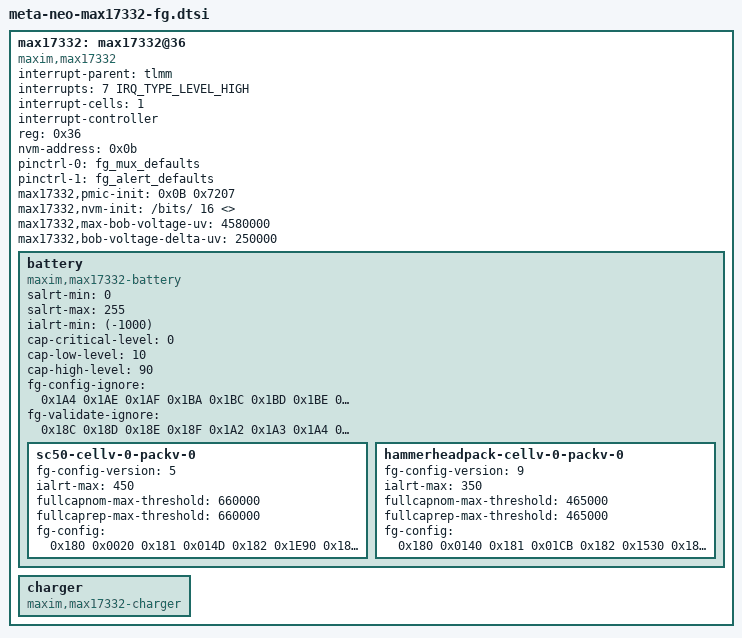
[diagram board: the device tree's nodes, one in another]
/*
MAX17332 is a multifunction device with battery, charger.
Required properties:
 - compatible : Must be "maxim,max17332".
 - interrupt-parent : The parent interrupt controller.
 - interrupts : Interrupt number.
 - interrupt-controller : Mark the device node as an interrupt controller.
 - interrupt-cells : Should be one.
	- The cell is the max17332 local IRQ number
 - max17332,pmic-init : Register values for initialization.
 - max17332,nvm-init : Register values for non-volatile memory initialization.
Nodes:
- battery, charger
*/

max17332: max17332@36 {
    compatible = "maxim,max17332";
    interrupt-parent = <&tlmm>;
    interrupts = <7 IRQ_TYPE_LEVEL_HIGH>;
    interrupt-cells = <1>;
    interrupt-controller;
    reg = <0x36>;
    status= "ok";
    nvm-address = /bits/ 8 <0x0b>;
    pinctrl-names = "default", "alert_enable";
    pinctrl-0 = <&fg_mux_defaults>;
    pinctrl-1 = <&fg_alert_defaults>;
    max17332,pmic-init = /bits/ 16 <0x0B 0x7207>;
    max17332,nvm-init = /bits/ 16 <>;
    max17332,max-bob-voltage-uv = <4580000>;
    max17332,bob-voltage-delta-uv = <250000>;

    battery {
        compatible = "maxim,max17332-battery";
        status = "ok";
        /* Battery */
        salrt-min			= <0>;			/* Percent */
        salrt-max			= <255>;		/* Percent. Setting to 255 (0xFF) which is a special value that disables the salrt-max */
        ialrt-min			= <(-1000)>;	/* mA */

        cap-critical-level		= /bits/ 8 <0>;
        cap-low-level		= /bits/ 8 <10>;
        cap-high-level		= /bits/ 8 <90>;
        /* fuel gauge configuration - ini version 9 */
        /* these set of fuel gauge registers will not
         * be written when updating the fg-config
         */
        fg-config-ignore    = /bits/ 16 <
            0x1A4 0x1AE 0x1AF 0x1BA
            0x1BC 0x1BD 0x1BE 0x1BF
            0x1E0 0x1E1 0x1E6 0x1E7
            0x1E8 0x1E9 0x1EA 0x1EB
            0x1EC 0x1ED 0x1EE 0x1EF>;
        fg-validate-ignore  = /bits/ 16 <
            0x18C 0x18D 0x18E 0x18F
            0x1A2 0x1A3 0x1A4 0x1A5 0x1A6 0x1A7 0x1A8 0x1A9 0x1AA 0x1AB 0x1AC 0x1AD 0x1AE 0x1AF
            0x1BA 0x1BB 0x1BC 0x1BD 0x1BE 0x1BF
            0x1C5 0x1CC
            0x1E0 0x1E1 0x1E2 0x1E3 0x1E4 0x1E5 0x1E6 0x1E7 0x1E8 0x1E9 0x1EA 0x1EB 0x1EC 0x1ED 0x1EE 0x1EF>;

        /* Pack specific settings */
        sc50-cellv-0-packv-0 {
            fg-config-version   = /bits/ 8 <5>;
            ialrt-max           = <450>;    /* mA */
            fullcapnom-max-threshold    = <660000>;
            fullcaprep-max-threshold    = <660000>;
            fg-config                   = /bits/ 16 <
                0x180  0x0020
                0x181  0x014D
                0x182  0x1E90
                0x183  0x0F00
                0x184  0x0E2D
                0x185  0x1003
                0x186  0x0A80
                0x187  0x0796
                0x188  0x0527
                0x189  0x06E0
                0x18A  0x08F3
                0x18B  0x03CC
                0x18C  0xE095
                0x18D  0x3CEC
                0x18E  0x16CE
                0x18F  0xFF01
                0x190  0x897B
                0x191  0xA248
                0x192  0xB7E8
                0x193  0xBA7C
                0x194  0xBD50
                0x195  0xBF08
                0x196  0xC23C
                0x197  0xC50A
                0x198  0xC96D
                0x199  0xD19D
                0x19A  0xD86F
                0x19B  0xDD34
                0x19C  0x0514
                0x19D  0x0000
                0x19E  0xA55A
                0x19F  0x2686
                0x1A0  0x3050
                0x1A1  0x0640
                0x1A2  0x0000
                0x1A3  0x0000
                0x1A4  0x0000
                0x1A5  0x0370
                0x1A6  0x0390
                0x1A7  0x0A03
                0x1A8  0x0000
                0x1A9  0x0370
                0x1AA  0x0000
                0x1AB  0x0000
                0x1AC  0x0000
                0x1AD  0x0000
                0x1AE  0x0000
                0x1AF  0x0000
                0x1B0  0xF217
                0x1B1  0x0204
                0x1B2  0x3870
                0x1B3  0x0B0B
                0x1B4  0x0010
                0x1B5  0x027D
                0x1B6  0x023C
                0x1B7  0x4241
                0x1B8  0x0000
                0x1B9  0x02A6
                0x1BA  0x0000
                0x1BB  0x0909
                0x1BC  0x0000
                0x1BD  0x0000
                0x1BE  0x0000
                0x1BF  0x0000
                0x1C0  0xC23E
                0x1C1  0x008C
                0x1C2  0x1E10
                0x1C3  0x4F72
                0x1C4  0x0075
                0x1C5  0x0AD0
                0x1C6  0x0000
                0x1C7  0x2000
                0x1C8  0x4003
                0x1C9  0x5188
                0x1CA  0x71B0
                0x1CB  0x0800
                0x1CC  0x04E0
                0x1CD  0x0000
                0x1CE  0x03EB
                0x1CF  0x000B
                0x1D0  0x660A
                0x1D1  0x3118
                0x1D2  0xF000
                0x1D3  0x2800
                0x1D4  0x7D00
                0x1D5  0x1113
                0x1D6  0x7A2F
                0x1D7  0x3021
                0x1D8  0xCBA8
                0x1D9  0x090A
                0x1DA  0x7A94
                0x1DB  0xBE25
                0x1DC  0x0478
                0x1DD  0xBDE0
                0x1DE  0x4358
                0x1DF  0x0000
                0x1E0  0x0000
                0x1E1  0x0000
                0x1E2  0x0000
                0x1E3  0x0000
                0x1E4  0x5800
                0x1E5  0x0000
                0x1E6  0x0000
                0x1E7  0x0000
                0x1E8  0x0000
                0x1E9  0x0000
                0x1EA  0x0000
                0x1EB  0x0000
                0x1EC  0x0000
                0x1ED  0x0000
                0x1EE  0x0000
                0x1EF  0x0000
            >;
        };
        hammerheadpack-cellv-0-packv-0 {
            fg-config-version   = /bits/ 8 <9>;
            ialrt-max           = <350>;	/* mA */
            fullcapnom-max-threshold    = <465000>;
            fullcaprep-max-threshold    = <465000>;
            fg-config                   = /bits/ 16 <
                0x180  0x0140
                0x181  0x01CB
                0x182  0x1530
                0x183  0x0F70
                0x184  0x140E
                0x185  0x1010
                0x186  0x0840
                0x187  0x07C7
                0x188  0x06F3
                0x189  0x06A0
                0x18A  0x06F5
                0x18B  0x05FF
                0x18C  0xDF95
                0x18D  0x3CEC
                0x18E  0x11CE
                0x18F  0xFF01
                0x190  0xA4FB
                0x191  0xAE89
                0x192  0xB791
                0x193  0xBACC
                0x194  0xBD10
                0x195  0xBE72
                0x196  0xC2CC
                0x197  0xC76D
                0x198  0xCAAF
                0x199  0xD1DD
                0x19A  0xD4DE
                0x19B  0xD9B1
                0x19C  0x3914
                0x19D  0x0000
                0x19E  0xA55A
                0x19F  0x2686
                0x1A0  0x0600
                0x1A1  0x0080
                0x1A2  0x0000
                0x1A3  0x0000
                0x1A4  0x0000
                0x1A5  0x026C
                0x1A6  0x0310
                0x1A7  0x1802
                0x1A8  0x0000
                0x1A9  0x026C
                0x1AA  0x0000
                0x1AB  0x0000
                0x1AC  0x0000
                0x1AD  0x0000
                0x1AE  0x0000
                0x1AF  0x0000
                0x1B0  0xF217
                0x1B1  0x0204
                0x1B2  0x3830
                0x1B3  0x0F8A
                0x1B4  0x0010
                0x1B5  0x027D
                0x1B6  0x023C
                0x1B7  0x4241
                0x1B8  0x0000
                0x1B9  0x02A6
                0x1BA  0x0000
                0x1BB  0x0909
                0x1BC  0x0000
                0x1BD  0x0000
                0x1BE  0x0000
                0x1BF  0x0000
                0x1C0  0x4209
                0x1C1  0x0063
                0x1C2  0x1E10
                0x1C3  0xE272
                0x1C4  0x003B
                0x1C5  0x05F0
                0x1C6  0x0000
                0x1C7  0x2000
                0x1C8  0x4003
                0x1C9  0x5188
                0x1CA  0x71B0
                0x1CB  0x0800
                0x1CC  0x04B0
                0x1CD  0x0000
                0x1CE  0x05B0
                0x1CF  0x000F
                0x1D0  0x660A
                0x1D1  0x3118
                0x1D2  0xF000
                0x1D3  0x1E00
                0x1D4  0x7D00
                0x1D5  0x1113
                0x1D6  0x7A2F
                0x1D7  0x3021
                0x1D8  0xCBA8
                0x1D9  0x090A
                0x1DA  0xAA8A
                0x1DB  0xBE25
                0x1DC  0x0478
                0x1DD  0xBDE0
                0x1DE  0x4358
                0x1DF  0x0000
                0x1E0  0x0000
                0x1E1  0x0000
                0x1E2  0x0000
                0x1E3  0x0000
                0x1E4  0xD800
                0x1E5  0x0000
                0x1E6  0x0000
                0x1E7  0x0000
                0x1E8  0x0000
                0x1E9  0x0000
                0x1EA  0x0000
                0x1EB  0x0000
                0x1EC  0x0000
                0x1ED  0x0000
                0x1EE  0x0000
                0x1EF  0x0000
            >;
        };
    };
    charger {
        compatible = "maxim,max17332-charger";
        status = "ok";
    };
};
